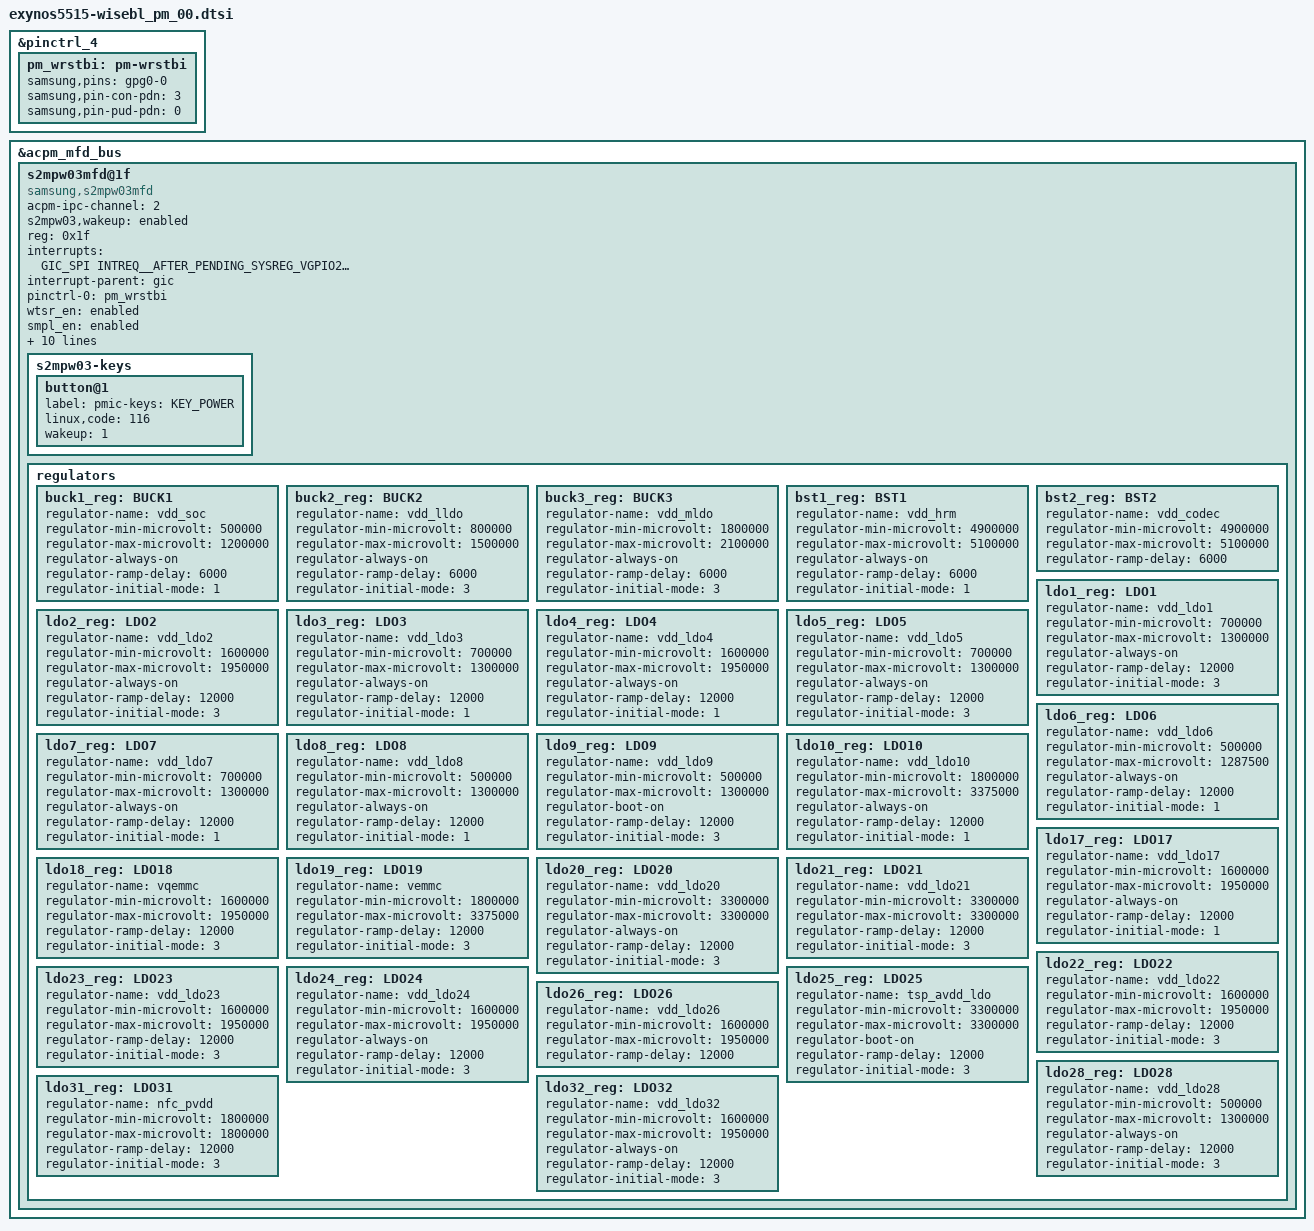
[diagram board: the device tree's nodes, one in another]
/*
 * SAMSUNG EXYNOS5515 Power Management device tree source
 *
 * Copyright (c) 2021 Samsung Electronics Co., Ltd.
 *		http://www.samsung.com
 *
 * This program is free software; you can redistribute it and/or modify
 * it under the terms of the GNU General Public License version 2 as
 * published by the Free Software Foundation.
 */

#include <dt-bindings/interrupt-controller/s5e5515.h>
#include "exynos5515-wisebl_pm_common.dtsi"


&pinctrl_4 {
	pm_wrstbi: pm-wrstbi {
		   samsung,pins = "gpg0-0";
		   samsung,pin-con-pdn = <3>;
		   samsung,pin-pud-pdn = <0>;
	};
};

&acpm_mfd_bus {
	status = "okay";
	#address-cells = <1>;
	#size-cells = <0>;
	s2mpw03mfd@1f {
		compatible = "samsung,s2mpw03mfd";
		acpm-ipc-channel = <2>;
		s2mpw03,wakeup = "enabled";
		reg = <0x1f>;
		interrupts = <GIC_SPI INTREQ__AFTER_PENDING_SYSREG_VGPIO2AP IRQ_TYPE_LEVEL_HIGH>;
		interrupt-parent = <&gic>;
		pinctrl-names = "default";
		pinctrl-0 = <&pm_wrstbi>;
		/* RTC: wtsr/smpl */
		wtsr_en = "enabled"; /* enable */
		smpl_en = "enabled"; /* enable */
		wtsr_timer_val = <3>;	/* 1000ms */
		smpl_timer_val = <4>;	/* 500ms */
		check_jigon = <0>; /* do not check jigon */
		/* RTC: If it's first boot, reset rtc to 1/1/2018 12:00:00(Wed) */
		init_time,sec = <0>;
		init_time,min = <0>;
		init_time,hour = <12>;
		init_time,mday = <1>;
		init_time,mon = <0>;
		init_time,year = <121>;
		init_time,wday = <5>;

		s2mpw03-keys {
			button@1 {
				label = "pmic-keys: KEY_POWER";
				linux,code = <116>;
				wakeup = <1>;
			};
		};

		regulators {
			buck1_reg: BUCK1 {
				regulator-name = "vdd_soc";
				regulator-min-microvolt = <500000>;
				regulator-max-microvolt = <1200000>;
				regulator-always-on;
				regulator-ramp-delay = <6000>;
				regulator-initial-mode = <1>;		/* V_PWREN_MIF */
			};
			buck2_reg: BUCK2 {
				regulator-name = "vdd_lldo";
				regulator-min-microvolt = <800000>;
				regulator-max-microvolt = <1500000>;
				regulator-always-on;
				regulator-ramp-delay = <6000>;
				regulator-initial-mode = <3>;		/* Always-on */
			};

			buck3_reg: BUCK3 {
				regulator-name = "vdd_mldo";
				regulator-min-microvolt = <1800000>;
				regulator-max-microvolt = <2100000>;
				regulator-always-on;
				regulator-ramp-delay = <6000>;
				regulator-initial-mode = <3>;		/* Always-on */
			};

			/*
			 *
			buck4_reg: BUCK4 {
				regulator-name = "vdd_cp";
				regulator-min-microvolt = <500000>;
				regulator-max-microvolt = <1200000>;
				regulator-always-on;
				regulator-ramp-delay = <6000>;
				regulator-initial-mode = <3>;
			};
			*/

			bst1_reg: BST1 {
				regulator-name = "vdd_hrm";
				regulator-min-microvolt = <4900000>;
				regulator-max-microvolt = <5100000>;
				regulator-always-on;
				regulator-ramp-delay = <6000>;
				regulator-initial-mode = <1>;
			};

			bst2_reg: BST2 {
				regulator-name = "vdd_codec";
				regulator-min-microvolt = <4900000>;
				regulator-max-microvolt = <5100000>;
				regulator-ramp-delay = <6000>;
			};

			ldo1_reg: LDO1 {
				regulator-name = "vdd_ldo1";
				regulator-min-microvolt = <700000>;
				regulator-max-microvolt = <1300000>;
				regulator-always-on;
				regulator-ramp-delay = <12000>;
				regulator-initial-mode = <3>;
			};

			ldo2_reg: LDO2 {
				regulator-name = "vdd_ldo2";
				regulator-min-microvolt = <1600000>;
				regulator-max-microvolt = <1950000>;
				regulator-always-on;
				regulator-ramp-delay = <12000>;
				regulator-initial-mode = <3>;
			};

			ldo3_reg: LDO3 {
				regulator-name = "vdd_ldo3";
				regulator-min-microvolt = <700000>;
				regulator-max-microvolt = <1300000>;
				regulator-always-on;
				regulator-ramp-delay = <12000>;
				regulator-initial-mode = <1>;		/* V_PWREN_MIF */
			};

			ldo4_reg: LDO4 {
				regulator-name = "vdd_ldo4";
				regulator-min-microvolt = <1600000>;
				regulator-max-microvolt = <1950000>;
				regulator-always-on;
				regulator-ramp-delay = <12000>;
				regulator-initial-mode = <1>;		/* V_PWREN_MIF */
			};

			ldo5_reg: LDO5 {
				regulator-name = "vdd_ldo5";
				regulator-min-microvolt = <700000>;
				regulator-max-microvolt = <1300000>;
				regulator-always-on;
				regulator-ramp-delay = <12000>;
				regulator-initial-mode = <3>;
			};

			ldo6_reg: LDO6 {
				regulator-name = "vdd_ldo6";
				regulator-min-microvolt = <500000>;
				regulator-max-microvolt = <1287500>;
				regulator-always-on;
				regulator-ramp-delay = <12000>;
				regulator-initial-mode = <1>;		/* V_PWREN_MIF */
			};

			ldo7_reg: LDO7 {
				regulator-name = "vdd_ldo7";
				regulator-min-microvolt = <700000>;
				regulator-max-microvolt = <1300000>;
				regulator-always-on;
				regulator-ramp-delay = <12000>;
				regulator-initial-mode = <1>;		/* V_PWREN_MIF */
			};

			ldo8_reg: LDO8 {
				regulator-name = "vdd_ldo8";
				regulator-min-microvolt = <500000>;
				regulator-max-microvolt = <1300000>;
				regulator-always-on;
				regulator-ramp-delay = <12000>;
				regulator-initial-mode = <1>;		/* V_PWREN_MIF */
			};

			ldo9_reg: LDO9 { /* VDD_VTS */
				regulator-name = "vdd_ldo9";
				regulator-min-microvolt = <500000>;
				regulator-max-microvolt = <1300000>;
				regulator-boot-on;
				regulator-ramp-delay = <12000>;
				regulator-initial-mode = <3>;
			};

			ldo10_reg: LDO10 {
				regulator-name = "vdd_ldo10";
				regulator-min-microvolt = <1800000>;
				regulator-max-microvolt = <3375000>;
				regulator-always-on;
				regulator-ramp-delay = <12000>;
				regulator-initial-mode = <1>;		/* V_PWREN_MIF */
			};

			/*
			 *
			ldo11_reg: LDO11 {
				regulator-name = "vdd_ldo11";
				regulator-min-microvolt = <700000>;
				regulator-max-microvolt = <1300000>;
				regulator-always-on;
				regulator-ramp-delay = <12000>;
				regulator-initial-mode = <3>;
			};

			ldo12_reg: LDO12 {
				regulator-name = "vdd_ldo12";
				regulator-min-microvolt = <700000>;
				regulator-max-microvolt = <1300000>;
				regulator-always-on;
				regulator-ramp-delay = <12000>;
				regulator-initial-mode = <3>;
			};

			ldo13_reg: LDO13 {
				regulator-name = "vdd_ldo13";
				regulator-min-microvolt = <1600000>;
				regulator-max-microvolt = <1950000>;
				regulator-always-on;
				regulator-ramp-delay = <12000>;
				regulator-initial-mode = <3>;
			};

			ldo14_reg: LDO14 {
				regulator-name = "vdd_ldo14";
				regulator-min-microvolt = <1800000>;
				regulator-max-microvolt = <3375000>;
				regulator-always-on;
				regulator-ramp-delay = <12000>;
				regulator-initial-mode = <3>;
			};

			ldo15_reg: LDO15 {
				regulator-name = "vdd_ldo15";
				regulator-min-microvolt = <700000>;
				regulator-max-microvolt = <1300000>;
				regulator-always-on;
				regulator-ramp-delay = <12000>;
				regulator-initial-mode = <3>;
			};

			ldo16_reg: LDO16 {
				regulator-name = "vdd_ldo16";
				regulator-min-microvolt = <1800000>;
				regulator-max-microvolt = <3375000>;
				regulator-always-on;
				regulator-ramp-delay = <12000>;
				regulator-initial-mode = <3>;
			};
			*/

			ldo17_reg: LDO17 {
				regulator-name = "vdd_ldo17";
				regulator-min-microvolt = <1600000>;
				regulator-max-microvolt = <1950000>;
				regulator-always-on;
				regulator-ramp-delay = <12000>;
				regulator-initial-mode = <1>;		/* V_PWREN_CLK */
			};

			ldo18_reg: LDO18 {/* VCCQ_MEM (VDD_EMMC_1P8) */
				regulator-name = "vqemmc";
				regulator-min-microvolt = <1600000>;
				regulator-max-microvolt = <1950000>;
				regulator-ramp-delay = <12000>;
				regulator-initial-mode = <3>;
			};

			ldo19_reg: LDO19 {/* VCC_MEM (VDD_EMMC_2P85) */
				regulator-name = "vemmc";
				regulator-min-microvolt = <1800000>;
				regulator-max-microvolt = <3375000>;
				regulator-ramp-delay = <12000>;
				regulator-initial-mode = <3>;
			};

			ldo20_reg: LDO20 {
				regulator-name = "vdd_ldo20";
				regulator-min-microvolt = <3300000>;
				regulator-max-microvolt = <3300000>;
				regulator-always-on;
				regulator-ramp-delay = <12000>;
				regulator-initial-mode = <3>;
			};

			ldo21_reg: LDO21 {
				regulator-name = "vdd_ldo21";
				regulator-min-microvolt = <3300000>;
				regulator-max-microvolt = <3300000>;
				regulator-ramp-delay = <12000>;
				regulator-initial-mode = <3>;
			};

			ldo22_reg: LDO22 {
				regulator-name = "vdd_ldo22";
				regulator-min-microvolt = <1600000>;
				regulator-max-microvolt = <1950000>;
				regulator-ramp-delay = <12000>;
				regulator-initial-mode = <3>;
			};

			ldo23_reg: LDO23 {
				regulator-name = "vdd_ldo23";
				regulator-min-microvolt = <1600000>;
				regulator-max-microvolt = <1950000>;
				regulator-ramp-delay = <12000>;
				regulator-initial-mode = <3>;
			};

			ldo24_reg: LDO24 {
				regulator-name = "vdd_ldo24";
				regulator-min-microvolt = <1600000>;
				regulator-max-microvolt = <1950000>;
				regulator-always-on;
				regulator-ramp-delay = <12000>;
				regulator-initial-mode = <3>;
			};

			ldo25_reg: LDO25 {
				regulator-name = "tsp_avdd_ldo";
				regulator-min-microvolt = <3300000>;
				regulator-max-microvolt = <3300000>;
				regulator-boot-on;
				regulator-ramp-delay = <12000>;
				regulator-initial-mode = <3>;
			};

			ldo26_reg: LDO26 {
				regulator-name = "vdd_ldo26";
				regulator-min-microvolt = <1600000>;
				regulator-max-microvolt = <1950000>;
				regulator-ramp-delay = <12000>;
			};

			ldo28_reg: LDO28 {
				regulator-name = "vdd_ldo28";
				regulator-min-microvolt = <500000>;
				regulator-max-microvolt = <1300000>;
				regulator-always-on;
				regulator-ramp-delay = <12000>;
				regulator-initial-mode = <3>;
			};

			ldo31_reg: LDO31 {
				regulator-name = "nfc_pvdd";
				regulator-min-microvolt = <1800000>;
				regulator-max-microvolt = <1800000>;
				regulator-ramp-delay = <12000>;
				regulator-initial-mode = <3>;
			};

			ldo32_reg: LDO32 {
				regulator-name = "vdd_ldo32";
				regulator-min-microvolt = <1600000>;
				regulator-max-microvolt = <1950000>;
				regulator-always-on;
				regulator-ramp-delay = <12000>;
				regulator-initial-mode = <3>;
			};
		}; // end of regulators
	}; // end of s2mpw03mfd@1f
}; // end of acpm_mfd_bus@12A60000

